# ATSAMRH707F18A register map
Vendor: Microchip Technology; Series: SAMRH707; File version: 0
CPU: CM7 r1p1, little endian, MPU, FPU, 3 interrupt priority bits
Registers are 32-bit, read-write, reset 0x0 unless marked. A register's access mark holds for its fields unless they carry their own. Offsets are from the block's base; [hi:lo] are bit positions; {n}, {i} and the like mark numbered series; 'fields as' and 'values as' point back to an identical list.

## CRCCU — Cyclic Redundancy Check Calculation Unit
Base 0x40018000; register names take the prefix CRCCU_
0x00 DSCR — CRCCU Descriptor Base Register
  [31:9] DSCR — Descriptor Base Address
0x08 DMA_EN wo — CRCCU DMA Enable Register
  [0] DMAEN — DMA Enable
0x0C DMA_DIS wo — CRCCU DMA Disable Register
  [0] DMADIS — DMA Disable
0x10 DMA_SR ro — CRCCU DMA Status Register
  [0] DMASR — DMA Status
0x14 DMA_IER wo — CRCCU DMA Interrupt Enable Register
  [0] DMAIER — Interrupt Enable
0x18 DMA_IDR wo — CRCCU DMA Interrupt Disable Register
  [0] DMAIDR — Interrupt Disable
0x1C DMA_IMR ro — CRCCU DMA Interrupt Mask Register
  [0] DMAIMR — Interrupt Mask
0x20 DMA_ISR ro — CRCCU DMA Interrupt Status Register
  [0] DMAISR — Interrupt Status
0x34 CR wo — CRCCU Control Register
  [0] RESET — CRC Computation Reset
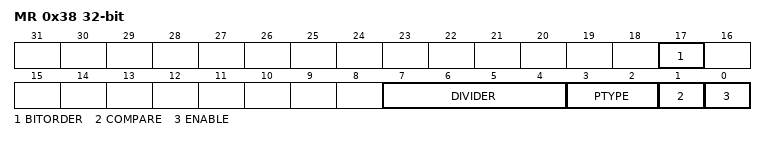
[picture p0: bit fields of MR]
0x38 MR — CRCCU Mode Register
  [17] BITORDER — Precomputation Bit Swap Operation of the CRC
    0=MSBFIRST (CRC computation is performed from the most significant bit to the least significant bit); 1=LSBFIRST (CRC computation is performed from the least significant bit to the most significant bit)
  [7:4] DIVIDER — Request Divider
  [3:2] PTYPE — Primitive Polynomial
    0=CCITT8023 (Polynom 0x04C11DB7); 1=CASTAGNOLI (Polynom 0x1EDC6F41); 2=CCITT16 (Polynom 0x1021)
  [1] COMPARE — CRC Compare
  [0] ENABLE — CRC Enable
0x3C SR ro — CRCCU Status Register
  [31:0] CRC — Cyclic Redundancy Check Value
0x40 IER wo — CRCCU Interrupt Enable Register
  [0] ERRIER — CRC Error Interrupt Enable
0x44 IDR wo — CRCCU Interrupt Disable Register
  [0] ERRIDR — CRC Error Interrupt Disable
0x48 IMR ro — CRCCU Interrupt Mask Register
  [0] ERRIMR — CRC Error Interrupt Mask
0x4C ISR ro — CRCCU Interrupt Status Register
  [0] ERRISR — CRC Error Interrupt Status

## FLEXRAMECC
Base 0x40100600; register names take the prefix FLEXRAMECC_
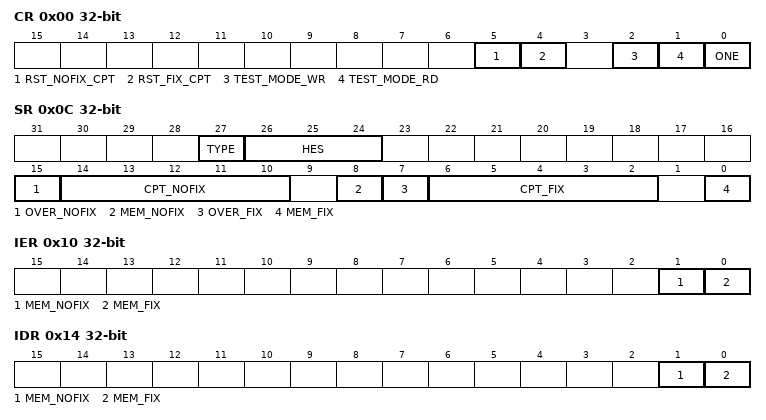
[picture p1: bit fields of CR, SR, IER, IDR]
0x00 CR — FLEXRAMECC Control Register
  [5] RST_NOFIX_CPT — reset the un-fixable error counter
  [4] RST_FIX_CPT — reset the fixable error counter
  [2] TEST_MODE_WR — test mode of ECC protection - write mode
  [1] TEST_MODE_RD — test mode of ECC protection - read mode
  [0] ONE — Shall be always write at '1'
0x04 TESTCB1 — FLEXRAMECC Test mode register 1
  [7:0] TCB1 — Test Check Bit
0x0C SR ro — FLEXRAMECC Status register
  [27] TYPE — write or read access
  [26:24] HES — Hardware Error Size
  [15] OVER_NOFIX — counter overflow
  [14:10] CPT_NOFIX — 5 bits counter
  [8] MEM_NOFIX — Un-fixable error status
  [7] OVER_FIX — counter overflow
  [6:2] CPT_FIX — 5 bits counter
  [0] MEM_FIX — Fixable error status
0x10 IER wo — FLEXRAMECC Interrupt Enable Register
  [1] MEM_NOFIX — Un-fixable error
  [0] MEM_FIX — Fixable error
0x14 IDR wo — FLEXRAMECC Interrupt Disable Register
  [1] MEM_NOFIX — un-fixable error
  [0] MEM_FIX — fixable error
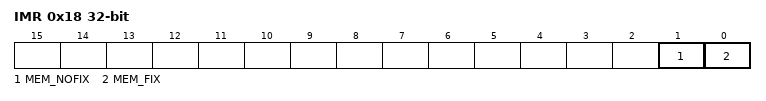
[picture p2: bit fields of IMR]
0x18 IMR ro — FLEXRAMECC Interrupt Mask Register
  [1] MEM_NOFIX — un-fixable error
  [0] MEM_FIX — fixable error
0x1C FAILAR ro — FLEXRAMECC Fail address register
  [31:0] ADDRESS — address of the error detected
0x20 FAILDR ro — FLEXRAMECC Fail data register
  [31:0] DATA — data error

## HEMC
Base 0x40080000; register names take the prefix HEMC_
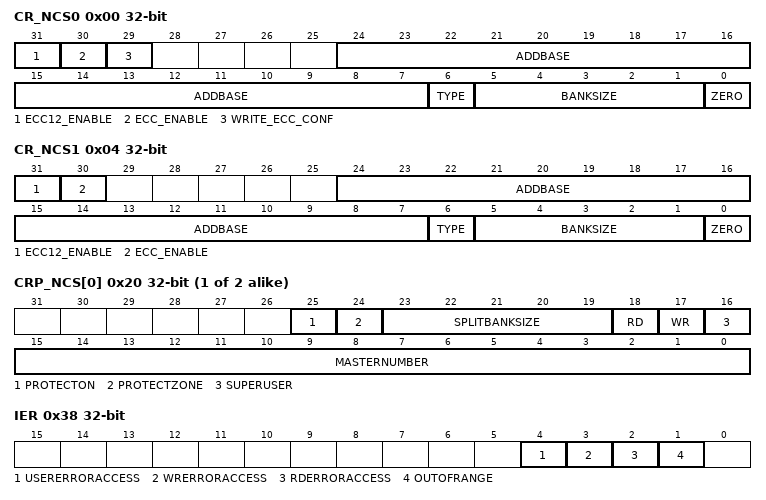
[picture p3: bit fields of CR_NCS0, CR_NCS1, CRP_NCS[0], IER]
0x00 CR_NCS0 — HEMC Control Register NCS 0
  [31] ECC12_ENABLE — BCH ECC enable
  [30] ECC_ENABLE — ECC Protection Enable
  [29] WRITE_ECC_CONF — ECC Configuration Protection Enable
  [24:7] ADDBASE — relative base address of NCS area
  [6] TYPE — type of memory used
  [5:1] BANKSIZE
    0=_8KB (8Kbytes); 1=_16KB (16Kbytes); 2=_32KB (32Kbytes); 3=_64KB (64Kbytes); 4=_128KB (128Kbytes); 5=_256KB (256Kbytes); 6=_512KB (512Kbytes); 7=_1MB (1Mbytes); 8=_2MB (2Mbytes); 31=NOT_USED
  [0] ZERO — fixed to 0
0x04 CR_NCS1 — HEMC Control Register NCS 1
  [31] ECC12_ENABLE — BCH ECC enable
  [30] ECC_ENABLE — ECC Protection Enable
  [24:7] ADDBASE — relative base address of NCS area
  [6] TYPE — type of memory used
  [5:1] BANKSIZE
    values as CR_NCS0.BANKSIZE
  [0] ZERO — fixed to 0
0x18 CTRL — HEMC Polarity Control register
  [0] POL — External control buffer active polarity
{0x20+4i} CRP_NCS[{i}] (i=0..1) — HEMC Control Register Protection NCS
  [25] PROTECTON — protection activation
  [24] PROTECTZONE — select area protected
  [23:19] SPLITBANKSIZE — bank size internal separation
  [18] RD — Read Access
  [17] WR — Write Access
  [16] SUPERUSER — User or Superuser access
  [15:0] MASTERNUMBER — Master Number ID
0x38 IER wo — HEMC Interrupt Enable Register
  [4] USERERRORACCESS — user or superuser access error
  [3] WRERRORACCESS — write access error
  [2] RDERRORACCESS — read access error
  [1] OUTOFRANGE
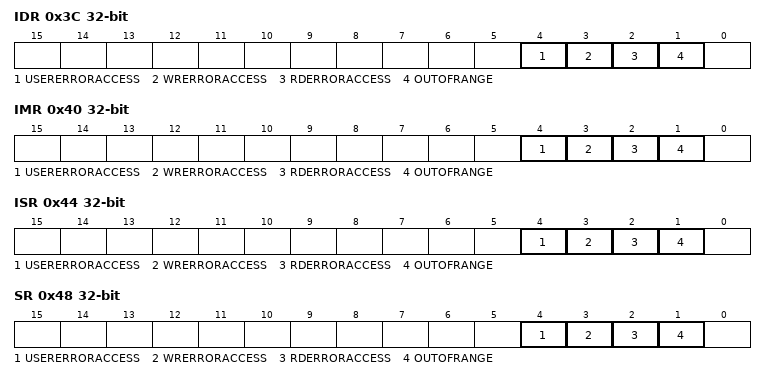
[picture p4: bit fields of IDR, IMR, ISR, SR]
0x3C IDR wo — HEMC Interrupt Disable Register
  fields as IER
0x40 IMR ro — HEMC Interrupt Mask Register
  fields as IER
0x44 ISR ro — HEMC Interrupt Status Register
  [4] USERERRORACCESS — User or SuperUser Error Access
  [3] WRERRORACCESS — Write access error
  [2] RDERRORACCESS — read access error
  [1] OUTOFRANGE
0x48 SR ro — HEMC Status Register
  [4] USERERRORACCESS — User or SuperUser Error Access
  [3] WRERRORACCESS — Write access error
  [2] RDERRORACCESS — Read access error
  [1] OUTOFRANGE
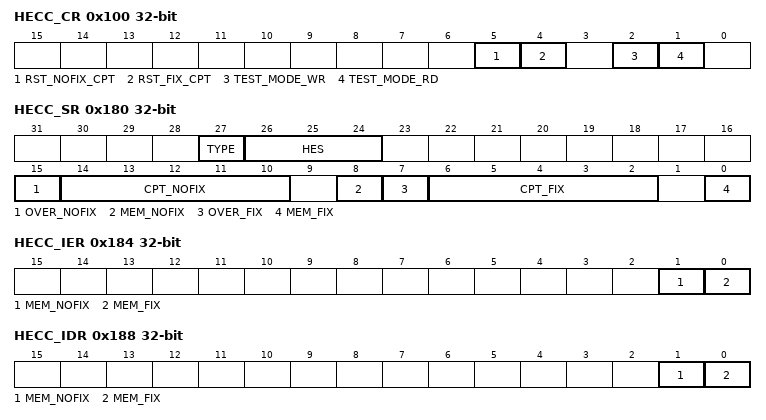
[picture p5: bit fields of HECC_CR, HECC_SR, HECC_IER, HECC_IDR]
0x100 HECC_CR — HECC Control Register Channel 0 (HSMC)
  [5] RST_NOFIX_CPT — reset the un-fixable error counter
  [4] RST_FIX_CPT — reset the fixable error counter
  [2] TEST_MODE_WR — test mode of ECC protection - write mode
  [1] TEST_MODE_RD — test mode of ECC protection - read mode
0x140 HECC_TESTCB — HECC Test mode Register Channel 0 (HSMC)
  [15:0] TCB1 — test check bit (16 bit)
0x180 HECC_SR ro — HECC Status Register
  [27] TYPE — write or read access
  [26:24] HES — Hardware Error Size
  [15] OVER_NOFIX — counter overflow
  [14:10] CPT_NOFIX — 5 bits counter
  [8] MEM_NOFIX — Un-fixable error status
  [7] OVER_FIX — counter overflow
  [6:2] CPT_FIX — 5 bits counter
  [0] MEM_FIX — Fixable error status
0x184 HECC_IER wo — HECC Interrupt Enable Register
  [1] MEM_NOFIX — Un-fixable error
  [0] MEM_FIX — Fixable error
0x188 HECC_IDR wo — HECC Interrupt Disable Register
  [1] MEM_NOFIX — un-fixable error
  [0] MEM_FIX — fixable error
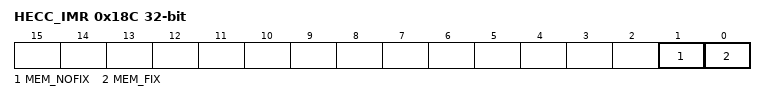
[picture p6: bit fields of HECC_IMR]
0x18C HECC_IMR ro — HECC Interrupt Mask Register
  [1] MEM_NOFIX — un-fixable error
  [0] MEM_FIX — fixable error
0x190 HECC_FAILAR ro — HECC Fail address register
  [31:0] ADDRESS — address of the error detected
0x194 HECC_FAILDR ro — HECC Fail data register
  [31:0] DATA — Data error detected
